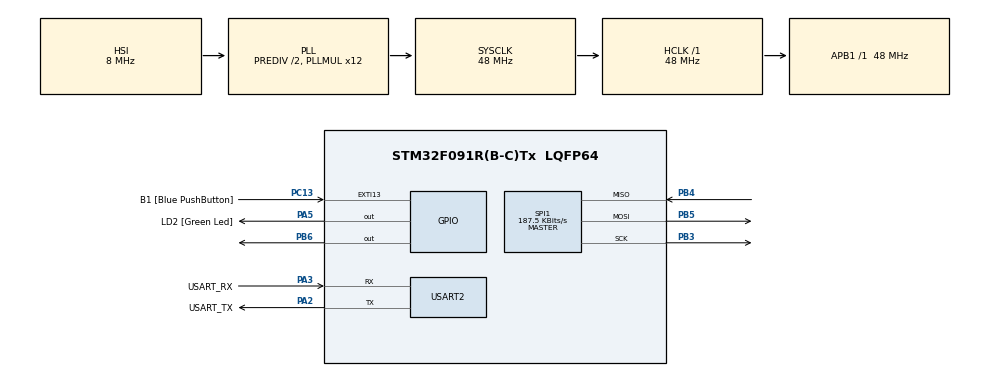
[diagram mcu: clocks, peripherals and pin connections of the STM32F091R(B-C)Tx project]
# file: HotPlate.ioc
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Dma.Request0=SPI1_RX
Dma.SPI1_RX.0.Direction=DMA_PERIPH_TO_MEMORY
Dma.SPI1_RX.0.Instance=DMA1_Channel2
Dma.SPI1_RX.0.MemDataAlignment=DMA_MDATAALIGN_BYTE
Dma.SPI1_RX.0.MemInc=DMA_MINC_ENABLE
Dma.SPI1_RX.0.Mode=DMA_NORMAL
Dma.SPI1_RX.0.PeriphDataAlignment=DMA_PDATAALIGN_BYTE
Dma.SPI1_RX.0.PeriphInc=DMA_PINC_DISABLE
Dma.SPI1_RX.0.Priority=DMA_PRIORITY_LOW
Mcu.Family=STM32F0
Mcu.Name=STM32F091R(B-C)Tx
Mcu.Package=LQFP64
NVIC.DMA1_Ch2_3_DMA2_Ch1_2_IRQn=true\:0\:0\:false\:false\:true\:false\:true\:true
PA13.GPIO_Label=TMS
PA13.Mode=Serial_Wire
PA13.Signal=SYS_SWDIO
PA14.GPIO_Label=TCK
PA14.Mode=Serial_Wire
PA14.Signal=SYS_SWCLK
PA2.GPIO_Label=USART_TX
PA2.GPIO_Mode=GPIO_MODE_AF_PP
PA2.GPIO_PuPd=GPIO_NOPULL
PA2.GPIO_Speed=GPIO_SPEED_FREQ_LOW
PA2.Mode=Asynchronous
PA2.Signal=USART2_TX
PA3.GPIO_Label=USART_RX
PA3.GPIO_Mode=GPIO_MODE_AF_PP
PA3.GPIO_PuPd=GPIO_NOPULL
PA3.GPIO_Speed=GPIO_SPEED_FREQ_LOW
PA3.Mode=Asynchronous
PA3.Signal=USART2_RX
PA5.GPIO_Label=LD2 [Green Led]
PA5.GPIO_Mode=GPIO_MODE_OUTPUT_PP
PA5.GPIO_PuPd=GPIO_NOPULL
PA5.GPIO_Speed=GPIO_SPEED_FREQ_LOW
PA5.Signal=GPIO_Output
PB3.Mode=Full_Duplex_Master
PB3.Signal=SPI1_SCK
PB4.Mode=Full_Duplex_Master
PB4.Signal=SPI1_MISO
PB5.Mode=Full_Duplex_Master
PB5.Signal=SPI1_MOSI
PB6.GPIO_FM6=__NULL
PB6.GPIO_ModeDefaultOutputPP=GPIO_MODE_OUTPUT_PP
PB6.GPIO_Speed=GPIO_SPEED_FREQ_HIGH
PB6.PinState=GPIO_PIN_SET
PB6.Signal=GPIO_Output
PC13.GPIO_Label=B1 [Blue PushButton]
PC13.GPIO_ModeDefaultEXTI=GPIO_MODE_IT_FALLING
PC13.Signal=GPXTI13
PC14OSC32_IN.Signal=RCC_OSC32_IN
PC15OSC32_OUT.Signal=RCC_OSC32_OUT
PF0-OSC_IN.Signal=RCC_OSC_IN
PF1-OSC_OUT.Signal=RCC_OSC_OUT
ProjectManager.HeapSize=0x200
ProjectManager.StackSize=0x400
ProjectManager.TargetToolchain=CMake
RCC.AHBFreq_Value=48000000
RCC.APB1Freq_Value=48000000
RCC.APB1TimFreq_Value=48000000
RCC.FLatency-AdvancedSettings=FLASH_LATENCY_1
RCC.HCLKFreq_Value=48000000
RCC.PLLDivider=RCC_PREDIV_DIV2
RCC.PLLMUL=RCC_PLL_MUL12
RCC.PREFETCH_ENABLE-AdvancedSettings=1
RCC.SYSCLKFreq_VALUE=48000000
RCC.SYSCLKSource=RCC_SYSCLKSOURCE_PLLCLK
SPI1.BaudRatePrescaler=SPI_BAUDRATEPRESCALER_256
SPI1.CLKPhase=SPI_PHASE_2EDGE
SPI1.CLKPolarity=SPI_POLARITY_HIGH
SPI1.CalculateBaudRate=187.5 KBits/s
SPI1.DataSize=SPI_DATASIZE_8BIT
SPI1.Direction=SPI_DIRECTION_2LINES
SPI1.Mode=SPI_MODE_MASTER
SPI1.VirtualType=VM_MASTER
USART2.VirtualMode=VM_ASYNC
USART2.VirtualMode-Asynchronous=VM_ASYNC
board=NUCLEO-F091RC

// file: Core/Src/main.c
/* USER CODE BEGIN Header */
/**
 ******************************************************************************
 * @file           : main.c
 * @brief          : Main program body
 ******************************************************************************
 * @attention
 *
 * Copyright (c) 2025 STMicroelectronics.
 * All rights reserved.
 *
 * This software is licensed under terms that can be found in the LICENSE file
 * in the root directory of this software component.
 * If no LICENSE file comes with this software, it is provided AS-IS.
 *
 ******************************************************************************
 */
/* USER CODE END Header */
#include "main.h"
#include "spi.c"
#include "AD7794.c"
#include <stdbool.h>

DMA_HandleTypeDef hdma_spi1_rx;

UART_HandleTypeDef huart2;

void SystemClock_Config(void);
static void MX_GPIO_Init(void);
static void MX_DMA_Init(void);
static void MX_USART2_UART_Init(void);

int main(void)
{

  /* MCU Configuration--------------------------------------------------------*/

  /* Reset of all peripherals, Initializes the Flash interface and the Systick. */
  HAL_Init();

  /* Configure the system clock */
  SystemClock_Config();

  /* Initialize all configured peripherals */
  MX_GPIO_Init();
  MX_DMA_Init();
  MX_SPI1_Init();
  MX_USART2_UART_Init();

  /* Infinite loop */
  /* USER CODE BEGIN WHILE */
  bool configured = false;
  while (1)
  {

    HAL_GPIO_WritePin(GPIOB_BASE,GPIO_PIN_6, GPIO_PIN_RESET);
    HAL_Delay(1000);
    if (!configured)
    {
      SetMode(Mode_MD_SCM | Mode_AMPCM | Mode_Chop_DIS |  Mode_Rate_242Hz_8ms);
      SetConfiguration(Conf_UB | Conf_G64 | Conf_Buf | Conf_Ch_TempSensor);
      configured = true;
    }
    ReadMode();
    ReadConfiguration();
    // while (1)
    // {
    //   ReadData();
    //   HAL_Delay(1000);
    // }

    //CheckStatusReady();

    // HAL_GPIO_TogglePin(GPIOB, GPIO_PIN_6);
    HAL_Delay(1000);
    // ReadMode();
    // ReadConfiguration();
    // ReadStatus();
    // ReadMode();

    // uint8_t RX_Buffer;
    // uint8_t TX_Buffer  = 0x48;
    // uint16_t conf = 0x1010;
    // uint16_t conf = 0b000101100001000;
    // uint16_t mode = 0x0101;
    // Write_16bit(Mode_Reg, mode);
    // Write_16bit(Conf_Reg, conf);

    // uint16_t data = Read_16bit(Mode_Reg);
    // uint16_t data2 = Read_16bit(Conf_Reg);
    // uint16_t data23 = Read_8bit(Stat_Reg);
    // HAL_GPIO_TogglePin(GPIOB, GPIO_PIN_6);

    /* USER CODE END WHILE */

    HAL_GPIO_WritePin(GPIOB_BASE,GPIO_PIN_6, GPIO_PIN_SET);
  }
}

void SystemClock_Config(void)
{
  RCC_OscInitTypeDef RCC_OscInitStruct = {0};
  RCC_ClkInitTypeDef RCC_ClkInitStruct = {0};
  RCC_PeriphCLKInitTypeDef PeriphClkInit = {0};

  /** Initializes the RCC Oscillators according to the specified parameters
  * in the RCC_OscInitTypeDef structure.
  */
  RCC_OscInitStruct.OscillatorType = RCC_OSCILLATORTYPE_HSI;
  RCC_OscInitStruct.HSIState = RCC_HSI_ON;
  RCC_OscInitStruct.HSICalibrationValue = RCC_HSICALIBRATION_DEFAULT;
  RCC_OscInitStruct.PLL.PLLState = RCC_PLL_ON;
  RCC_OscInitStruct.PLL.PLLSource = RCC_PLLSOURCE_HSI;
  RCC_OscInitStruct.PLL.PLLMUL = RCC_PLL_MUL12;
  RCC_OscInitStruct.PLL.PREDIV = RCC_PREDIV_DIV2;
  if (HAL_RCC_OscConfig(&RCC_OscInitStruct) != HAL_OK)
  {
    Error_Handler();
  }

  /** Initializes the CPU, AHB and APB buses clocks
  */
  RCC_ClkInitStruct.ClockType = RCC_CLOCKTYPE_HCLK|RCC_CLOCKTYPE_SYSCLK
                              |RCC_CLOCKTYPE_PCLK1;
  RCC_ClkInitStruct.SYSCLKSource = RCC_SYSCLKSOURCE_PLLCLK;
  RCC_ClkInitStruct.AHBCLKDivider = RCC_SYSCLK_DIV1;
  RCC_ClkInitStruct.APB1CLKDivider = RCC_HCLK_DIV1;

  if (HAL_RCC_ClockConfig(&RCC_ClkInitStruct, FLASH_LATENCY_1) != HAL_OK)
  {
    Error_Handler();
  }
  PeriphClkInit.PeriphClockSelection = RCC_PERIPHCLK_USART2;
  PeriphClkInit.Usart2ClockSelection = RCC_USART2CLKSOURCE_PCLK1;
  if (HAL_RCCEx_PeriphCLKConfig(&PeriphClkInit) != HAL_OK)
  {
    Error_Handler();
  }
}

static void MX_USART2_UART_Init(void)
{

  huart2.Instance = USART2;
  huart2.Init.BaudRate = 115200;
  huart2.Init.WordLength = UART_WORDLENGTH_8B;
  huart2.Init.StopBits = UART_STOPBITS_1;
  huart2.Init.Parity = UART_PARITY_NONE;
  huart2.Init.Mode = UART_MODE_TX_RX;
  huart2.Init.HwFlowCtl = UART_HWCONTROL_NONE;
  huart2.Init.OverSampling = UART_OVERSAMPLING_16;
  huart2.Init.OneBitSampling = UART_ONE_BIT_SAMPLE_DISABLE;
  huart2.AdvancedInit.AdvFeatureInit = UART_ADVFEATURE_NO_INIT;
  if (HAL_UART_Init(&huart2) != HAL_OK)
  {
    Error_Handler();
  }

}

static void MX_DMA_Init(void)
{

  /* DMA controller clock enable */
  __HAL_RCC_DMA1_CLK_ENABLE();

  /* DMA interrupt init */
  /* DMA1_Ch2_3_DMA2_Ch1_2_IRQn interrupt configuration */
  HAL_NVIC_SetPriority(DMA1_Ch2_3_DMA2_Ch1_2_IRQn, 0, 0);
  HAL_NVIC_EnableIRQ(DMA1_Ch2_3_DMA2_Ch1_2_IRQn);

}

static void MX_GPIO_Init(void)
{
  GPIO_InitTypeDef GPIO_InitStruct = {0};

  /* GPIO Ports Clock Enable */
  __HAL_RCC_GPIOC_CLK_ENABLE();
  __HAL_RCC_GPIOF_CLK_ENABLE();
  __HAL_RCC_GPIOA_CLK_ENABLE();
  __HAL_RCC_GPIOB_CLK_ENABLE();

  /*Configure GPIO pin Output Level */
  HAL_GPIO_WritePin(LD2_GPIO_Port, LD2_Pin, GPIO_PIN_RESET);

  /*Configure GPIO pin Output Level */
  HAL_GPIO_WritePin(GPIOB, GPIO_PIN_6, GPIO_PIN_SET);

  /*Configure GPIO pin : B1_Pin */
  GPIO_InitStruct.Pin = B1_Pin;
  GPIO_InitStruct.Mode = GPIO_MODE_IT_FALLING;
  GPIO_InitStruct.Pull = GPIO_NOPULL;
  HAL_GPIO_Init(B1_GPIO_Port, &GPIO_InitStruct);

  /*Configure GPIO pin : LD2_Pin */
  GPIO_InitStruct.Pin = LD2_Pin;
  GPIO_InitStruct.Mode = GPIO_MODE_OUTPUT_PP;
  GPIO_InitStruct.Pull = GPIO_NOPULL;
  GPIO_InitStruct.Speed = GPIO_SPEED_FREQ_LOW;
  HAL_GPIO_Init(LD2_GPIO_Port, &GPIO_InitStruct);

  /*Configure GPIO pin : PB6 */
  GPIO_InitStruct.Pin = GPIO_PIN_6;
  GPIO_InitStruct.Mode = GPIO_MODE_OUTPUT_PP;
  GPIO_InitStruct.Pull = GPIO_NOPULL;
  GPIO_InitStruct.Speed = GPIO_SPEED_FREQ_HIGH;
  HAL_GPIO_Init(GPIOB, &GPIO_InitStruct);

}

void Error_Handler(void)
{
  __disable_irq();
  while (1)
  {
  }
}
